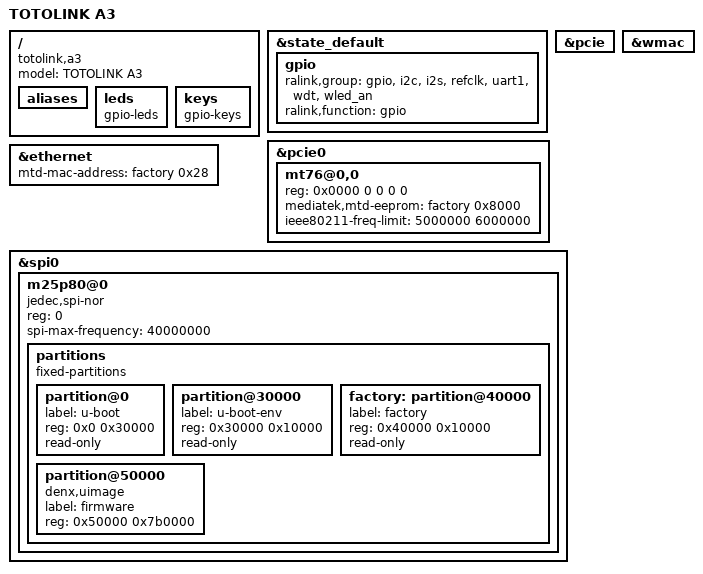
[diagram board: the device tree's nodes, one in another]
// SPDX-License-Identifier: GPL-2.0-or-later OR MIT
/dts-v1/;

#include "mt7628an.dtsi"

#include <dt-bindings/gpio/gpio.h>
#include <dt-bindings/input/input.h>

/ {
	compatible = "totolink,a3", "mediatek,mt7628dan";
	model = "TOTOLINK A3";

	aliases {
		/*
		led-boot = &led_sys;
		led-failsafe = &led_sys;
		led-running = &led_sys;
		led-upgrade = &led_sys;
		*/
	};

	leds {
		compatible = "gpio-leds";
		/*
		available leds: POWER, CPU, WIFI, WAN, LAN1/2
		led_sys: sys {
			label = "a3:blue:sys";
			gpios = <&gpio0 11 GPIO_ACTIVE_LOW>;
		};

		wifi {
			label = "a3:blue:wifi";
			gpios = <&gpio1 12 GPIO_ACTIVE_LOW>;
			linux,default-trigger = "phy0tpt";
		};
		
		heartbeat {
			Label = "a3:blue:heartbeat";
			gpios = <&gpio1 13 GPIO_ACTIVE_LOW>;
                        linux,default-trigger = "heartbeat";
		};
		eth0 {
                        Label = "a3:blue:eth0";
                        gpios = <&gpio1 13 GPIO_ACTIVE_LOW>;
                        linux,default-trigger = "eth0";
                };
		eth1 {
                        Label = "a3:blue:eth1";
                        gpios = <&gpio1 13 GPIO_ACTIVE_LOW>;
                        linux,default-trigger = "eth1";
                };
		wan {
                        Label = "a3:blue:wan";
                        gpios = <&gpio1 13 GPIO_ACTIVE_LOW>;
                        linux,default-trigger = "wan";
                };



*/
	};

	keys {
		compatible = "gpio-keys";
		/*
		This one is also available on the A3.
		There is also a separate wds button.
		reset {
			label = "reset";
			gpios = <&gpio1 6 GPIO_ACTIVE_LOW>;
			linux,code = <KEY_RESTART>;
		};
		*/
	};
};
/*
See a couple lines up.
&gpio1 {
	gpio_modem_reset {
		gpio-hog;
		gpios = <13 GPIO_ACTIVE_HIGH>;
		output-high;
		line-name = "modem-reset";
	};
};
*/
&state_default {
	gpio {
		ralink,group = "gpio", "i2c", "i2s", "refclk", "uart1", "wdt", "wled_an";
		ralink,function = "gpio";
	};
};

&pcie {
	status = "okay";
};

&pcie0 {
	mt76@0,0 {
		reg = <0x0000 0 0 0 0>;
		mediatek,mtd-eeprom = <&factory 0x8000>;
		ieee80211-freq-limit = <5000000 6000000>;
	};
};

&wmac {
	status = "okay";
};

&ethernet {
	mtd-mac-address = <&factory 0x28>;
};

&spi0 {
	status = "okay";

	m25p80@0 {
		compatible = "jedec,spi-nor";
		reg = <0>;
		spi-max-frequency = <40000000>;

		partitions {
			compatible = "fixed-partitions";
			#address-cells = <1>;
			#size-cells = <1>;

			partition@0 {
				label = "u-boot";
				reg = <0x0 0x30000>;
				read-only;
			};

			partition@30000 {
				label = "u-boot-env";
				reg = <0x30000 0x10000>;
				read-only;
			};

			factory: partition@40000 {
				label = "factory";
				reg = <0x40000 0x10000>;
				read-only;
			};

			partition@50000 {
				compatible = "denx,uimage";
				label = "firmware";
				reg = <0x50000 0x7b0000>;
			};
		};
	};
};
